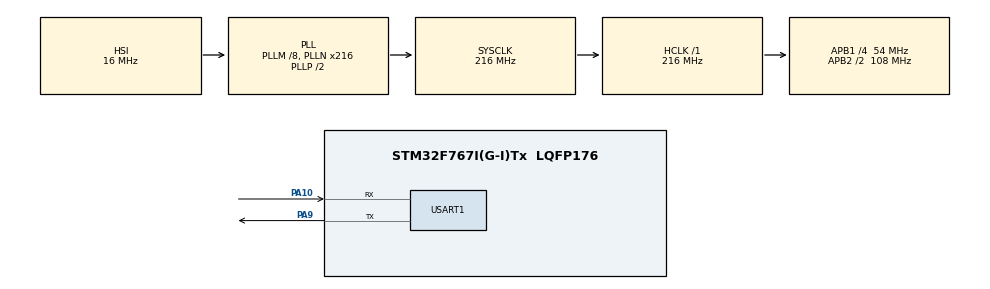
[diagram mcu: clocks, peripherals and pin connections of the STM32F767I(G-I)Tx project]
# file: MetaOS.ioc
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Mcu.Family=STM32F7
VP_SYS_VS_tim6.Mode=TIM6
RCC.CortexFreq_Value=216000000
PA10.Mode=Asynchronous
NVIC.TIM6_DAC_IRQn=true\:0\:0\:false\:false\:true\:false\:true
RCC.APB1CLKDivider=RCC_HCLK_DIV4
RCC.SYSCLKSource=RCC_SYSCLKSOURCE_PLLCLK
ProjectManager.StackSize=0x400
USART1.VirtualMode-Asynchronous=VM_ASYNC
PA13.Signal=SYS_JTMS-SWDIO
PA9.Mode=Asynchronous
ProjectManager.TargetToolchain=Makefile
PH0/OSC_IN.Mode=HSE-External-Oscillator
RCC.HCLKFreq_Value=216000000
RCC.APB2TimFreq_Value=216000000
PA9.Signal=USART1_TX
PH1/OSC_OUT.Signal=RCC_OSC_OUT
RCC.USBFreq_Value=216000000
RCC.LSE_VALUE=32768
RCC.AHBFreq_Value=216000000
RCC.HSE_VALUE=25000000
board=custom
RCC.VCOOutputFreq_Value=432000000
PH0/OSC_IN.Signal=RCC_OSC_IN
RCC.APB2Freq_Value=108000000
PA14.Mode=Serial_Wire
PA13.Mode=Serial_Wire
PH1/OSC_OUT.Mode=HSE-External-Oscillator
Mcu.Name=STM32F767I(G-I)Tx
RCC.SYSCLKFreq_VALUE=216000000
Mcu.Package=LQFP176
NVIC.TimeBase=TIM6_DAC_IRQn
NVIC.TimeBaseIP=TIM6
PA10.Signal=USART1_RX
PA14.Signal=SYS_JTCK-SWCLK
ProjectManager.HeapSize=0x200
RCC.HSI_VALUE=16000000
NVIC.PriorityGroup=NVIC_PRIORITYGROUP_4
RCC.APB2CLKDivider=RCC_HCLK_DIV2
RCC.PLLM=8
RCC.PLLN=216
RCC.APB1TimFreq_Value=108000000
RCC.APB1Freq_Value=54000000

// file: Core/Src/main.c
/* USER CODE BEGIN Header */
/**
 ******************************************************************************
 * @file           : main.c
 * @brief          : Main program body
 ******************************************************************************
 * @attention
 *
 * <h2><center>&copy; Copyright (c) 2022 STMicroelectronics.
 * All rights reserved.</center></h2>
 *
 * This software component is licensed by ST under BSD 3-Clause license,
 * the "License"; You may not use this file except in compliance with the
 * License. You may obtain a copy of the License at:
 *                        opensource.org/licenses/BSD-3-Clause
 *
 ******************************************************************************
 */
/* USER CODE END Header */
#include "main.h"
#include "gpio.h"
#include "usart.h"

/* USER CODE BEGIN Includes */
#include "LinkList.h"
#include "DualLinkList.h"
#include "DualCircleList.h"
#include "Queue.h"
/* USER CODE END Includes */

/* USER CODE BEGIN PTD */
struct list_node
{
  struct dual_link_list_node node;
  int data;
};
/* USER CODE END PTD */

void SystemClock_Config(void);

int main(void)
{

  /* MCU Configuration--------------------------------------------------------*/

  /* Reset of all peripherals, Initializes the Flash interface and the Systick. */
  HAL_Init();

  /* Configure the system clock */
  SystemClock_Config();

  /* Initialize all configured peripherals */
  MX_GPIO_Init();
  MX_USART1_UART_Init();
  /* USER CODE BEGIN 2 */
  Queue *list = queue_create(LIST_DYNAMIC, NULL);

  for (int i = 0; i < 10; i++)
  {
    struct list_node *node = malloc(sizeof(struct list_node));
    if (node)
    {
      node->data = i;
      queue_add(list, node);
    }
  }
  /* USER CODE END 2 */

  /* Infinite loop */
  while (1)
  {
    list_begin(list);
    for(int i = 0; i < list_length(list); i++)
    {
      struct list_node *node = list_current(list);
      printf("%d ", node->data);
      list_next(list);
    }
    printf("\r\n");

    queue_rotate(list);
    HAL_Delay(1000);
  }
}

void SystemClock_Config(void)
{
  RCC_OscInitTypeDef RCC_OscInitStruct = {0};
  RCC_ClkInitTypeDef RCC_ClkInitStruct = {0};

  /** Configure the main internal regulator output voltage
   */
  __HAL_RCC_PWR_CLK_ENABLE();
  __HAL_PWR_VOLTAGESCALING_CONFIG(PWR_REGULATOR_VOLTAGE_SCALE1);
  /** Initializes the RCC Oscillators according to the specified parameters
   * in the RCC_OscInitTypeDef structure.
   */
  RCC_OscInitStruct.OscillatorType = RCC_OSCILLATORTYPE_HSI;
  RCC_OscInitStruct.HSIState = RCC_HSI_ON;
  RCC_OscInitStruct.HSICalibrationValue = RCC_HSICALIBRATION_DEFAULT;
  RCC_OscInitStruct.PLL.PLLState = RCC_PLL_ON;
  RCC_OscInitStruct.PLL.PLLSource = RCC_PLLSOURCE_HSI;
  RCC_OscInitStruct.PLL.PLLM = 8;
  RCC_OscInitStruct.PLL.PLLN = 216;
  RCC_OscInitStruct.PLL.PLLP = RCC_PLLP_DIV2;
  RCC_OscInitStruct.PLL.PLLQ = 2;
  if (HAL_RCC_OscConfig(&RCC_OscInitStruct) != HAL_OK)
  {
    Error_Handler();
  }
  /** Activate the Over-Drive mode
   */
  if (HAL_PWREx_EnableOverDrive() != HAL_OK)
  {
    Error_Handler();
  }
  /** Initializes the CPU, AHB and APB buses clocks
   */
  RCC_ClkInitStruct.ClockType = RCC_CLOCKTYPE_HCLK | RCC_CLOCKTYPE_SYSCLK | RCC_CLOCKTYPE_PCLK1 | RCC_CLOCKTYPE_PCLK2;
  RCC_ClkInitStruct.SYSCLKSource = RCC_SYSCLKSOURCE_PLLCLK;
  RCC_ClkInitStruct.AHBCLKDivider = RCC_SYSCLK_DIV1;
  RCC_ClkInitStruct.APB1CLKDivider = RCC_HCLK_DIV4;
  RCC_ClkInitStruct.APB2CLKDivider = RCC_HCLK_DIV2;

  if (HAL_RCC_ClockConfig(&RCC_ClkInitStruct, FLASH_LATENCY_7) != HAL_OK)
  {
    Error_Handler();
  }
}

void HAL_TIM_PeriodElapsedCallback(TIM_HandleTypeDef *htim)
{
  if (htim->Instance == TIM6)
  {
    HAL_IncTick();
  }
}

void Error_Handler(void)
{
  __disable_irq();
  while (1)
  {
  }
}

/************************ (C) COPYRIGHT STMicroelectronics *****END OF FILE****/
